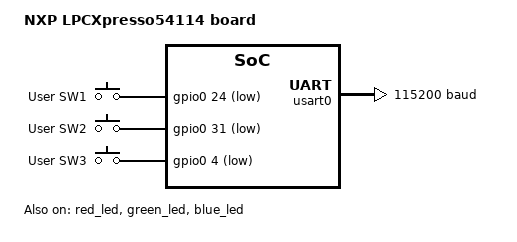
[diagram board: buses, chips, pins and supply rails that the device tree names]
/*
 * Copyright (c) 2017, NXP
 *
 * SPDX-License-Identifier: Apache-2.0
 */

/dts-v1/;

#include <nxp/nxp_lpc55S6x_m33_cpu0.dtsi>
#include "lpcxpresso55S69.dtsi"

/ {
	model = "NXP LPCXpresso54114 board";
	compatible = "nxp,lpc54xxx", "nxp,lpc";

	aliases{
		sw0 = &user_button_1;
		sw1 = &user_button_2;
		sw2 = &user_button_3;
	};

	chosen {
		zephyr,sram = &sram0;
		zephyr,flash = &flash0;
		zephyr,console = &usart0;
		zephyr,shell-uart = &usart0;
	};

	gpio_keys {
		compatible = "gpio-keys";
		user_button_1: button_0 {
			label = "User SW1";
			gpios = <&gpio0 24 GPIO_INT_ACTIVE_LOW>;
		};
		user_button_2: button_1 {
			label = "User SW2";
			gpios = <&gpio0 31 GPIO_INT_ACTIVE_LOW>;
		};
		user_button_3: button_2 {
			label = "User SW3";
			gpios = <&gpio0 4 GPIO_INT_ACTIVE_LOW>;
		};
	};
};

&usart0 {
	status = "ok";
	current-speed = <115200>;
};

&red_led {
	status = "ok";
};

&green_led {
	status = "ok";
};

&blue_led {
	status = "ok";
};
